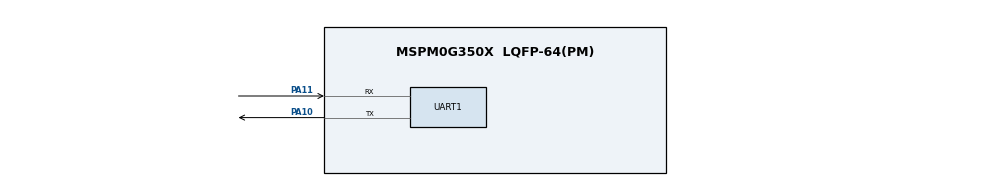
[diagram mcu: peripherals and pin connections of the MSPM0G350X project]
/**
 * @cliArgs --device "MSPM0G350X" --part "Default" --package "LQFP-64(PM)" --product "mspm0_sdk@2.02.00.05"
 * @versions {"tool":"1.21.0+3721"}
 */

/**
 * Import the modules used in this configuration.
 */
const DAC12  = scripting.addModule("/ti/driverlib/DAC12");
const SYSCTL = scripting.addModule("/ti/driverlib/SYSCTL");
const UART   = scripting.addModule("/ti/driverlib/UART", {}, false);
const UART1  = UART.addInstance();

/**
 * Write custom configuration values to the imported modules.
 */
DAC12.dacOutputPinEn     = true;
DAC12.dacRepresentation  = "TWOS_COMPLEMENT";
DAC12.dacAmplifier       = "ON";
DAC12.OutPinConfig.$name = "ti_driverlib_gpio_GPIOPinGeneric2";

const Board = scripting.addModule("/ti/driverlib/Board", {}, false);

SYSCTL.forceDefaultClkConfig = true;
SYSCTL.MFPCLKEn              = true;

UART1.$name                             = "TERMINAL_UART";
UART1.ovsRate                           = "8";
UART1.targetBaudRate                    = 4000000;
UART1.enableFIFO                        = true;
UART1.rxFifoThreshold                   = "DL_UART_RX_FIFO_LEVEL_ONE_ENTRY";
UART1.enabledInterrupts                 = ["DMA_DONE_RX","DMA_DONE_TX"];
UART1.enabledDMARXTriggers              = "DL_UART_DMA_INTERRUPT_RX";
UART1.enabledDMATXTriggers              = "DL_UART_DMA_INTERRUPT_TX";
UART1.txFifoThreshold                   = "DL_UART_TX_FIFO_LEVEL_EMPTY";
UART1.peripheral.$assign                = "UART0";
UART1.peripheral.rxPin.$assign          = "PA11";
UART1.peripheral.txPin.$assign          = "PA10";
UART1.txPinConfig.$name                 = "ti_driverlib_gpio_GPIOPinGeneric0";
UART1.txPinConfig.direction             = scripting.forceWrite("OUTPUT");
UART1.txPinConfig.hideOutputInversion   = scripting.forceWrite(false);
UART1.txPinConfig.onlyInternalResistor  = scripting.forceWrite(false);
UART1.txPinConfig.passedPeripheralType  = scripting.forceWrite("Digital");
UART1.rxPinConfig.$name                 = "ti_driverlib_gpio_GPIOPinGeneric1";
UART1.rxPinConfig.hideOutputInversion   = scripting.forceWrite(false);
UART1.rxPinConfig.onlyInternalResistor  = scripting.forceWrite(false);
UART1.rxPinConfig.passedPeripheralType  = scripting.forceWrite("Digital");
UART1.DMA_CHANNEL_RX.$name              = "DMA_CH_TERM_RX";
UART1.DMA_CHANNEL_RX.addressMode        = "f2b";
UART1.DMA_CHANNEL_RX.srcLength          = "BYTE";
UART1.DMA_CHANNEL_RX.dstLength          = "BYTE";
UART1.DMA_CHANNEL_RX.enableInterrupt    = true;
UART1.DMA_CHANNEL_RX.peripheral.$assign = "DMA_CH3";
UART1.DMA_CHANNEL_TX.$name              = "DMA_CH_TERM_TX";
UART1.DMA_CHANNEL_TX.addressMode        = "b2f";
UART1.DMA_CHANNEL_TX.srcLength          = "BYTE";
UART1.DMA_CHANNEL_TX.dstLength          = "BYTE";
UART1.DMA_CHANNEL_TX.enableInterrupt    = true;
UART1.DMA_CHANNEL_TX.peripheral.$assign = "DMA_CH4";

/**
 * Pinmux solution for unlocked pins/peripherals. This ensures that minor changes to the automatic solver in a future
 * version of the tool will not impact the pinmux you originally saw.  These lines can be completely deleted in order to
 * re-solve from scratch.
 */
DAC12.peripheral.$suggestSolution          = "DAC0";
DAC12.peripheral.OutPin.$suggestSolution   = "PA15";
Board.peripheral.$suggestSolution          = "DEBUGSS";
Board.peripheral.swclkPin.$suggestSolution = "PA20";
Board.peripheral.swdioPin.$suggestSolution = "PA19";
SYSCTL.peripheral.$suggestSolution         = "SYSCTL";
